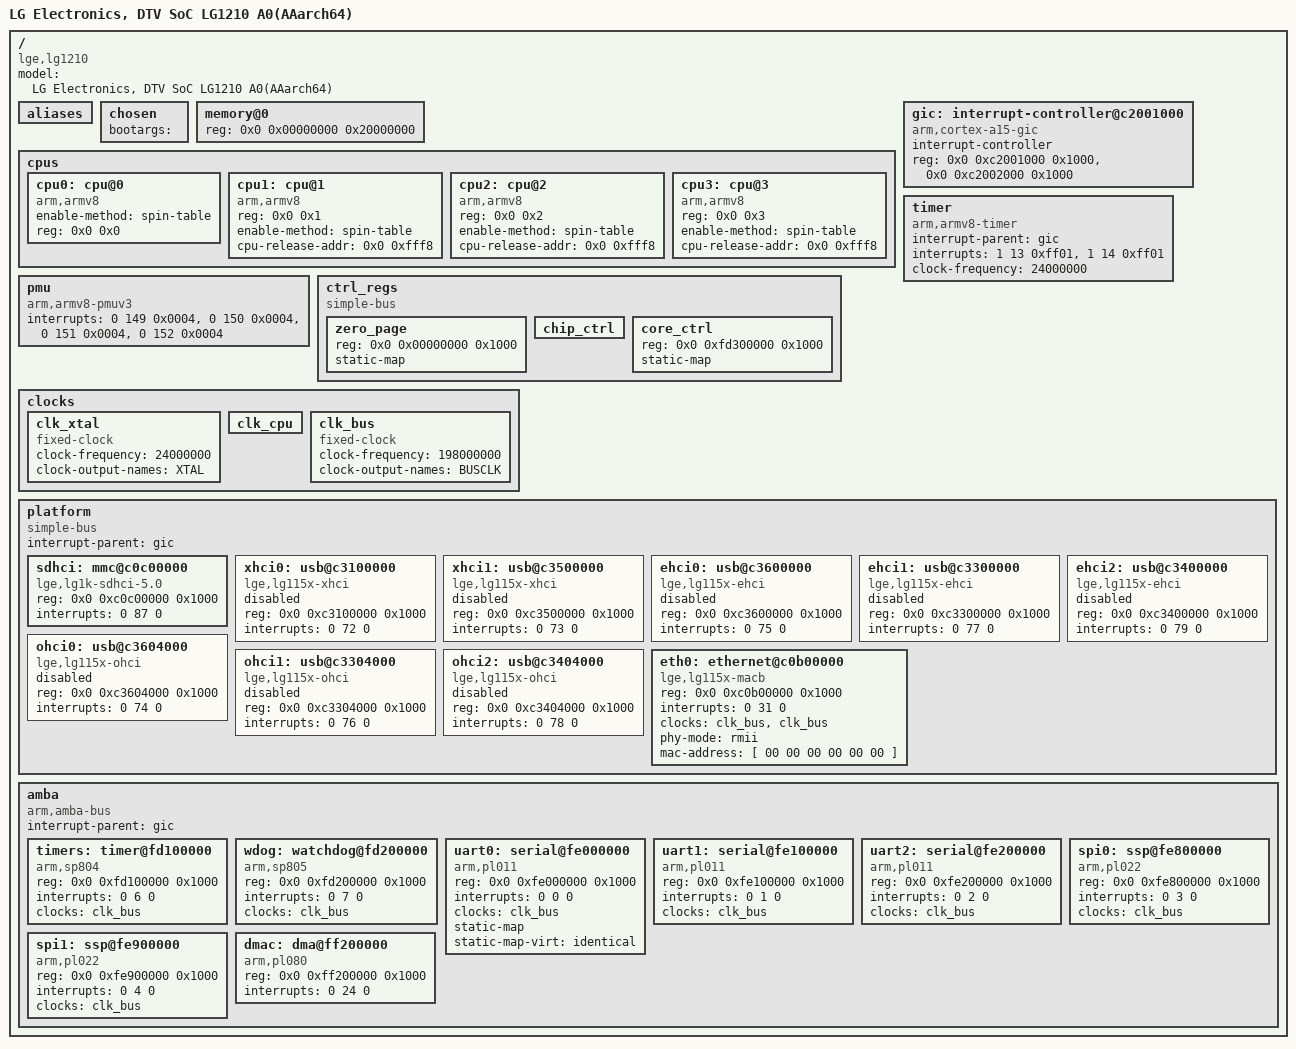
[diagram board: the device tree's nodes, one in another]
/dts-v1/;

/ {
	#address-cells = <2>;
	#size-cells = <1>;

	model = "LG Electronics, DTV SoC LG1210 A0(AAarch64)";
	compatible = "lge,lg1210";

	aliases {
	};

	chosen {
		bootargs = "";
	};

	memory@0 {
		device_type = "memory";
		reg = <0x0 0x00000000 0x20000000>;
	};

	cpus {
		#address-cells = <2>;
		#size-cells = <0>;

		cpu0: cpu@0 {
			device_type = "cpu";
			compatible = "arm,armv8";
			enable-method = "spin-table";
			reg = <0x0 0x0>;
		};
		cpu1: cpu@1 {
			device_type = "cpu";
			compatible = "arm,armv8";
			reg = <0x0 0x1>;
			enable-method = "spin-table";
			cpu-release-addr = <0x0 0xfff8>;
		};
		cpu2: cpu@2 {
			device_type = "cpu";
			compatible = "arm,armv8";
			reg = <0x0 0x2>;
			enable-method = "spin-table";
			cpu-release-addr = <0x0 0xfff8>;
		};
		cpu3: cpu@3 {
			device_type = "cpu";
			compatible = "arm,armv8";
			reg = <0x0 0x3>;
			enable-method = "spin-table";
			cpu-release-addr = <0x0 0xfff8>;
		};
	};

	gic: interrupt-controller@c2001000 {
		#interrupt-cells = <3>;

		compatible = "arm,cortex-a15-gic";
		interrupt-controller;
		reg = <0x0 0xc2001000 0x1000>,
		      <0x0 0xc2002000 0x1000>;
	};

	timer {
		compatible = "arm,armv8-timer";
		interrupt-parent = <&gic>;
		interrupts = <1 13 0xff01>,
		             <1 14 0xff01>;
		clock-frequency = <24000000>;
	};

	pmu {
		compatible = "arm,armv8-pmuv3";
		interrupts = <0 149 0x0004>,
		             <0 150 0x0004>,
		             <0 151 0x0004>,
			     <0 152 0x0004>;
	};

	ctrl_regs {
		#address-cells = <2>;
		#size-cells = <1>;

		compatible = "simple-bus";
		ranges;

		zero_page: zero_page {
			reg = <0x0 0x00000000 0x1000>;
			static-map;
		};
		chip_ctrl: chip_ctrl {
		};
		core_ctrl: core_ctrl {
			reg = <0x0 0xfd300000 0x1000>;
			static-map;
		};
	};

	clocks {
		clk_xtal: clk_xtal {
			#clock-cells = <0>;

			compatible = "fixed-clock";
			clock-frequency = <24000000>;
			clock-output-names = "XTAL";
		};
		clk_cpu: clk_cpu {
		};
		clk_bus: clk_bus {
			#clock-cells = <0>;

			compatible = "fixed-clock";
			clock-frequency = <198000000>;
			clock-output-names = "BUSCLK";
		};
	};

	platform {
		#address-cells = <2>;
		#size-cells = <1>;

		compatible = "simple-bus";
		interrupt-parent = <&gic>;
		ranges;

		sdhci: mmc@c0c00000 {
			compatible = "lge,lg1k-sdhci-5.0";
			reg = <0x0 0xc0c00000 0x1000>;
			interrupts = <0 87 0>;
		};
		xhci0: usb@c3100000 {
			compatible = "lge,lg115x-xhci", "xhci-platform";
			reg = <0x0 0xc3100000 0x1000>;
			interrupts = <0 72 0>;
			status = "skip";
		};
		xhci1: usb@c3500000 {
			compatible = "lge,lg115x-xhci", "xhci-platform";
			reg = <0x0 0xc3500000 0x1000>;
			interrupts = <0 73 0>;
			status = "skip";
		};
		ehci0: usb@c3600000 {
			compatible = "lge,lg115x-ehci", "ehci-platform";
			reg = <0x0 0xc3600000 0x1000>;
			interrupts = <0 75 0>;
			status = "skip";
		};
		ehci1: usb@c3300000 {
			compatible = "lge,lg115x-ehci", "ehci-platform";
			reg = <0x0 0xc3300000 0x1000>;
			interrupts = <0 77 0>;
			status = "skip";
		};
		ehci2: usb@c3400000 {
			compatible = "lge,lg115x-ehci", "ehci-platform";
			reg = <0x0 0xc3400000 0x1000>;
			interrupts = <0 79 0>;
			status = "skip";
		};
		ohci0: usb@c3604000 {
			compatible = "lge,lg115x-ohci", "ohci-platform";
			reg = <0x0 0xc3604000 0x1000>;
			interrupts = <0 74 0>;
			status = "skip";
		};
		ohci1: usb@c3304000 {
			compatible = "lge,lg115x-ohci", "ohci-platform";
			reg = <0x0 0xc3304000 0x1000>;
			interrupts = <0 76 0>;
			status = "skip";
		};
		ohci2: usb@c3404000 {
			compatible = "lge,lg115x-ohci", "ohci-platform";
			reg = <0x0 0xc3404000 0x1000>;
			interrupts = <0 78 0>;
			status = "skip";
		};
		eth0: ethernet@c0b00000 {
			compatible = "lge,lg115x-macb", "cdns,gem";
			reg = <0x0 0xc0b00000 0x1000>;
			interrupts = <0 31 0>;
			clocks = <&clk_bus>, <&clk_bus>;
			clock-names = "hclk", "pclk";
			phy-mode = "rmii";
			/* Filled in by lxboot */
			mac-address = [ 00 00 00 00 00 00 ];
		};
	};

	amba {
		#address-cells = <2>;
		#size-cells = <1>;
		#interrupts-cells = <3>;

		compatible = "arm,amba-bus";
		interrupt-parent = <&gic>;
		ranges;

		timers: timer@fd100000 {
			compatible = "arm,sp804";
			reg = <0x0 0xfd100000 0x1000>;
			interrupts = <0 6 0>;
			clocks = <&clk_bus>;
			clock-names = "apb_pclk";
		};
		wdog: watchdog@fd200000 {
			compatible = "arm,sp805", "arm,primecell";
			reg = <0x0 0xfd200000 0x1000>;
			interrupts = <0 7 0>;
			clocks = <&clk_bus>;
			clock-names = "apb_pclk";
		};
		uart0: serial@fe000000 {
			compatible = "arm,pl011", "arm,primecell";
			reg = <0x0 0xfe000000 0x1000>;
			interrupts = <0 0 0>;
			clocks = <&clk_bus>;
			clock-names = "apb_pclk";
			static-map;
			static-map-virt = "identical";
		};
		uart1: serial@fe100000 {
			compatible = "arm,pl011", "arm,primecell";
			reg = <0x0 0xfe100000 0x1000>;
			interrupts = <0 1 0>;
			clocks = <&clk_bus>;
			clock-names = "apb_pclk";
		};
		uart2: serial@fe200000 {
			compatible = "arm,pl011", "arm,primecell";
			reg = <0x0 0xfe200000 0x1000>;
			interrupts = <0 2 0>;
			clocks = <&clk_bus>;
			clock-names = "apb_pclk";
		};
		spi0: ssp@fe800000 {
			compatible = "arm,pl022", "arm,primecell";
			reg = <0x0 0xfe800000 0x1000>;
			interrupts = <0 3 0>;
			clocks = <&clk_bus>;
			clock-names = "apb_pclk";
		};
		spi1: ssp@fe900000 {
			compatible = "arm,pl022", "arm,primecell";
			reg = <0x0 0xfe900000 0x1000>;
			interrupts = <0 4 0>;
			clocks = <&clk_bus>;
			clock-names = "apb_pclk";
		};
		dmac: dma@ff200000 {
			compatible = "arm,pl080", "arm,primecell";
			reg = <0x0 0xff200000 0x1000>;
			interrupts = <0 24 0>;
		};
	};
};
